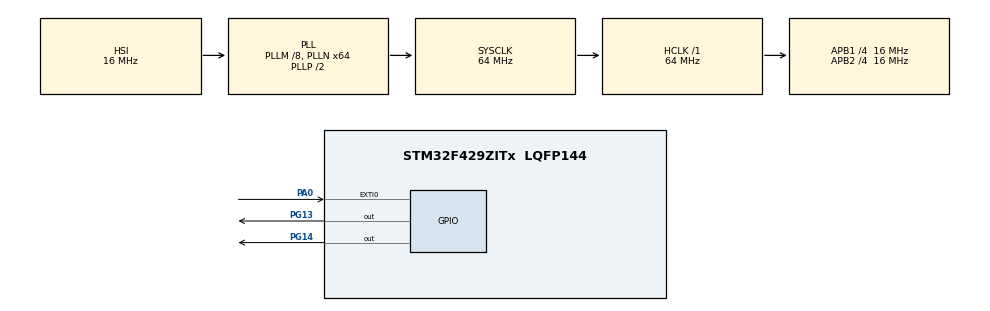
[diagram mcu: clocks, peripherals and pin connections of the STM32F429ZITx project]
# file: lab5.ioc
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Mcu.Family=STM32F4
Mcu.Name=STM32F429ZITx
Mcu.Package=LQFP144
NVIC.EXTI0_IRQn=true\:0\:0\:false\:false\:true\:true\:true\:true
NVIC.PriorityGroup=NVIC_PRIORITYGROUP_0
NVIC.TIM1_UP_TIM10_IRQn=true\:0\:0\:false\:false\:true\:true\:true\:true
NVIC.TIM6_DAC_IRQn=true\:0\:0\:false\:false\:true\:true\:true\:true
NVIC.TIM7_IRQn=true\:0\:0\:false\:false\:true\:true\:true\:true
PA0/WKUP.GPIO_ModeDefaultEXTI=GPIO_MODE_IT_RISING_FALLING
PA0/WKUP.Signal=GPXTI0
PG13.Signal=GPIO_Output
PG14.Signal=GPIO_Output
ProjectManager.HeapSize=0x200
ProjectManager.StackSize=0x400
ProjectManager.TargetToolchain=Makefile
RCC.48MHZClocksFreq_Value=18285714.285714287
RCC.AHBFreq_Value=64000000
RCC.APB1CLKDivider=RCC_HCLK_DIV4
RCC.APB1Freq_Value=16000000
RCC.APB1TimFreq_Value=32000000
RCC.APB2CLKDivider=RCC_HCLK_DIV4
RCC.APB2Freq_Value=16000000
RCC.APB2TimFreq_Value=32000000
RCC.CortexFreq_Value=64000000
RCC.HCLKFreq_Value=64000000
RCC.HSE_VALUE=8000000
RCC.HSI_VALUE=16000000
RCC.LSE_VALUE=32768
RCC.PLLM=8
RCC.PLLN=64
RCC.PLLQ=7
RCC.SYSCLKFreq_VALUE=64000000
RCC.SYSCLKSource=RCC_SYSCLKSOURCE_PLLCLK
RCC.VCOOutputFreq_Value=128000000
TIM1.Prescaler=20000
TIM6.Period=1000
TIM6.Prescaler=15999
TIM7.Period=123
TIM7.Prescaler=15999
VP_TIM1_VS_ClockSourceINT.Mode=Internal
VP_TIM6_VS_ClockSourceINT.Mode=Enable_Timer
VP_TIM7_VS_ClockSourceINT.Mode=Enable_Timer
board=STM32F429I-DISC1

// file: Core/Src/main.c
/* USER CODE BEGIN Header */
/**
  ******************************************************************************
  * @file           : main.c
  * @brief          : Main program body
  ******************************************************************************
  * @attention
  *
  * Copyright (c) 2025 STMicroelectronics.
  * All rights reserved.
  *
  * This software is licensed under terms that can be found in the LICENSE file
  * in the root directory of this software component.
  * If no LICENSE file comes with this software, it is provided AS-IS.
  *
  ******************************************************************************
  */
/* USER CODE END Header */
#include "main.h"
#include "stm32f4xx_hal_gpio.h"

TIM_HandleTypeDef htim1;
TIM_HandleTypeDef htim6;
TIM_HandleTypeDef htim7;

void SystemClock_Config(void);
static void MX_GPIO_Init(void);
static void MX_TIM6_Init(void);
static void MX_TIM1_Init(void);
static void MX_TIM7_Init(void);

/* USER CODE BEGIN 0 */

void HAL_GPIO_EXTI_Callback(uint16_t GPIO_Pin){
  if(HAL_GPIO_ReadPin(GPIOA,GPIO_PIN_0)){
    HAL_TIM_Base_Start_IT(&htim6);
  }else{
    HAL_TIM_Base_Stop_IT(&htim6);
  }
}
void HAL_TIM_PeriodElapsedCallback(TIM_HandleTypeDef *htim){
  if(htim->Instance == TIM7){
    HAL_GPIO_TogglePin(GPIOG, GPIO_PIN_13);
    return;
  }
  if(htim->Instance == TIM6){
    HAL_GPIO_TogglePin(GPIOG, GPIO_PIN_14);
    return;
  }
}
/* USER CODE END 0 */

int main(void)
{

  /* MCU Configuration--------------------------------------------------------*/

  /* Reset of all peripherals, Initializes the Flash interface and the Systick. */
  HAL_Init();

  /* Configure the system clock */
  SystemClock_Config();

  /* Initialize all configured peripherals */
  MX_GPIO_Init();
  MX_TIM6_Init();
  MX_TIM1_Init();
  MX_TIM7_Init();
  /* USER CODE BEGIN 2 */
  /*HAL_TIM_Base_Start_IT(&htim6);*/
  HAL_TIM_Base_Start_IT(&htim7);
  HAL_TIM_Base_Start_IT(&htim1);
  int counter = 0;
  /* USER CODE END 2 */

  /* Infinite loop */
  /* USER CODE BEGIN WHILE */
  while (1)
  {
    /*counter = __HAL_TIM_GET_COUNTER(&htim6);*/
    /*if(HAL_GPIO_ReadPin(GPIOA,GPIO_PIN_0)){*/
    /*  HAL_TIM_Base_Start_IT(&htim6);*/
    /*}else{*/
    /*  HAL_TIM_Base_Stop_IT(&htim6);*/
    /*}*/
    /* USER CODE END WHILE */

  }
}

void SystemClock_Config(void)
{
  RCC_OscInitTypeDef RCC_OscInitStruct = {0};
  RCC_ClkInitTypeDef RCC_ClkInitStruct = {0};

  /** Configure the main internal regulator output voltage
  */
  __HAL_RCC_PWR_CLK_ENABLE();
  __HAL_PWR_VOLTAGESCALING_CONFIG(PWR_REGULATOR_VOLTAGE_SCALE3);

  /** Initializes the RCC Oscillators according to the specified parameters
  * in the RCC_OscInitTypeDef structure.
  */
  RCC_OscInitStruct.OscillatorType = RCC_OSCILLATORTYPE_HSI;
  RCC_OscInitStruct.HSIState = RCC_HSI_ON;
  RCC_OscInitStruct.HSICalibrationValue = RCC_HSICALIBRATION_DEFAULT;
  RCC_OscInitStruct.PLL.PLLState = RCC_PLL_ON;
  RCC_OscInitStruct.PLL.PLLSource = RCC_PLLSOURCE_HSI;
  RCC_OscInitStruct.PLL.PLLM = 8;
  RCC_OscInitStruct.PLL.PLLN = 64;
  RCC_OscInitStruct.PLL.PLLP = RCC_PLLP_DIV2;
  RCC_OscInitStruct.PLL.PLLQ = 7;
  if (HAL_RCC_OscConfig(&RCC_OscInitStruct) != HAL_OK)
  {
    Error_Handler();
  }

  /** Initializes the CPU, AHB and APB buses clocks
  */
  RCC_ClkInitStruct.ClockType = RCC_CLOCKTYPE_HCLK|RCC_CLOCKTYPE_SYSCLK
                              |RCC_CLOCKTYPE_PCLK1|RCC_CLOCKTYPE_PCLK2;
  RCC_ClkInitStruct.SYSCLKSource = RCC_SYSCLKSOURCE_PLLCLK;
  RCC_ClkInitStruct.AHBCLKDivider = RCC_SYSCLK_DIV1;
  RCC_ClkInitStruct.APB1CLKDivider = RCC_HCLK_DIV4;
  RCC_ClkInitStruct.APB2CLKDivider = RCC_HCLK_DIV4;

  if (HAL_RCC_ClockConfig(&RCC_ClkInitStruct, FLASH_LATENCY_2) != HAL_OK)
  {
    Error_Handler();
  }
}

static void MX_TIM1_Init(void)
{

  TIM_ClockConfigTypeDef sClockSourceConfig = {0};
  TIM_MasterConfigTypeDef sMasterConfig = {0};

  htim1.Instance = TIM1;
  htim1.Init.Prescaler = 20000;
  htim1.Init.CounterMode = TIM_COUNTERMODE_UP;
  htim1.Init.Period = 65535;
  htim1.Init.ClockDivision = TIM_CLOCKDIVISION_DIV1;
  htim1.Init.RepetitionCounter = 0;
  htim1.Init.AutoReloadPreload = TIM_AUTORELOAD_PRELOAD_DISABLE;
  if (HAL_TIM_Base_Init(&htim1) != HAL_OK)
  {
    Error_Handler();
  }
  sClockSourceConfig.ClockSource = TIM_CLOCKSOURCE_INTERNAL;
  if (HAL_TIM_ConfigClockSource(&htim1, &sClockSourceConfig) != HAL_OK)
  {
    Error_Handler();
  }
  sMasterConfig.MasterOutputTrigger = TIM_TRGO_RESET;
  sMasterConfig.MasterSlaveMode = TIM_MASTERSLAVEMODE_DISABLE;
  if (HAL_TIMEx_MasterConfigSynchronization(&htim1, &sMasterConfig) != HAL_OK)
  {
    Error_Handler();
  }

}

static void MX_TIM6_Init(void)
{

  TIM_MasterConfigTypeDef sMasterConfig = {0};

  htim6.Instance = TIM6;
  htim6.Init.Prescaler = 15999;
  htim6.Init.CounterMode = TIM_COUNTERMODE_UP;
  htim6.Init.Period = 1000;
  htim6.Init.AutoReloadPreload = TIM_AUTORELOAD_PRELOAD_DISABLE;
  if (HAL_TIM_Base_Init(&htim6) != HAL_OK)
  {
    Error_Handler();
  }
  sMasterConfig.MasterOutputTrigger = TIM_TRGO_RESET;
  sMasterConfig.MasterSlaveMode = TIM_MASTERSLAVEMODE_DISABLE;
  if (HAL_TIMEx_MasterConfigSynchronization(&htim6, &sMasterConfig) != HAL_OK)
  {
    Error_Handler();
  }

}

static void MX_TIM7_Init(void)
{

  TIM_MasterConfigTypeDef sMasterConfig = {0};

  htim7.Instance = TIM7;
  htim7.Init.Prescaler = 15999;
  htim7.Init.CounterMode = TIM_COUNTERMODE_UP;
  htim7.Init.Period = 123;
  htim7.Init.AutoReloadPreload = TIM_AUTORELOAD_PRELOAD_DISABLE;
  if (HAL_TIM_Base_Init(&htim7) != HAL_OK)
  {
    Error_Handler();
  }
  sMasterConfig.MasterOutputTrigger = TIM_TRGO_RESET;
  sMasterConfig.MasterSlaveMode = TIM_MASTERSLAVEMODE_DISABLE;
  if (HAL_TIMEx_MasterConfigSynchronization(&htim7, &sMasterConfig) != HAL_OK)
  {
    Error_Handler();
  }

}

static void MX_GPIO_Init(void)
{
  GPIO_InitTypeDef GPIO_InitStruct = {0};

  /* GPIO Ports Clock Enable */
  __HAL_RCC_GPIOA_CLK_ENABLE();
  __HAL_RCC_GPIOG_CLK_ENABLE();

  /*Configure GPIO pin Output Level */
  HAL_GPIO_WritePin(GPIOG, GPIO_PIN_13|GPIO_PIN_14, GPIO_PIN_RESET);

  /*Configure GPIO pin : PA0 */
  GPIO_InitStruct.Pin = GPIO_PIN_0;
  GPIO_InitStruct.Mode = GPIO_MODE_IT_RISING_FALLING;
  GPIO_InitStruct.Pull = GPIO_NOPULL;
  HAL_GPIO_Init(GPIOA, &GPIO_InitStruct);

  /*Configure GPIO pins : PG13 PG14 */
  GPIO_InitStruct.Pin = GPIO_PIN_13|GPIO_PIN_14;
  GPIO_InitStruct.Mode = GPIO_MODE_OUTPUT_PP;
  GPIO_InitStruct.Pull = GPIO_NOPULL;
  GPIO_InitStruct.Speed = GPIO_SPEED_FREQ_LOW;
  HAL_GPIO_Init(GPIOG, &GPIO_InitStruct);

  /* EXTI interrupt init*/
  HAL_NVIC_SetPriority(EXTI0_IRQn, 0, 0);
  HAL_NVIC_EnableIRQ(EXTI0_IRQn);

}

void Error_Handler(void)
{
  __disable_irq();
  while (1)
  {
  }
}
